# STM32N645 register map
File version: 1.0
CPU: CM55 r0p1, little endian, no MPU, FPU, vendor SysTick, 8 interrupt priority bits
Registers are 32-bit, read-write, reset 0x0 unless marked. A register's access mark holds for its fields unless they carry their own. Offsets are from the block's base; [hi:lo] are bit positions.

## ADC12 — ADC common registers
Base 0x40022300
Same registers: ADC12_S 0x50022300
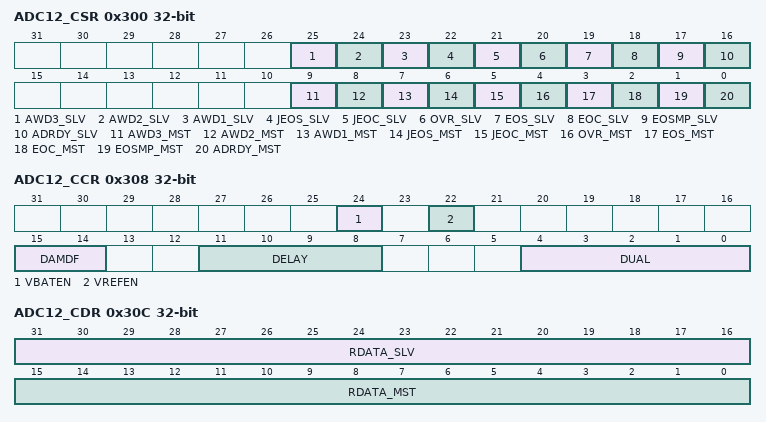
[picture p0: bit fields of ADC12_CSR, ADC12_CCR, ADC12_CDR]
0x300 ADC12_CSR ro — ADC12 common status register
  [25] AWD3_SLV — Analog watchdog 3 flag of the slave ADC
  [24] AWD2_SLV — Analog watchdog 2 flag of the slave ADC
  [23] AWD1_SLV — Analog watchdog 1 flag of the slave ADC
  [22] JEOS_SLV — End of injected sequence flag of the slave ADC
  [21] JEOC_SLV — End of injected conversion flag of the slave ADC
  [20] OVR_SLV — Overrun flag of the slave ADC
  [19] EOS_SLV — End of regular sequence flag of the slave ADC. This bit is a copy of the EOS bit in the corresponding ADC_ISR register.
  [18] EOC_SLV — End of regular conversion of the slave ADC
  [17] EOSMP_SLV — End of Sampling phase flag of the slave ADC
  [16] ADRDY_SLV — Slave ADC ready
  [9] AWD3_MST — Analog watchdog 3 flag of the master ADC
  [8] AWD2_MST — Analog watchdog 2 flag of the master ADC
  [7] AWD1_MST — Analog watchdog 1 flag of the master ADC
  [6] JEOS_MST — End of injected sequence flag of the master ADC
  [5] JEOC_MST — End of injected conversion flag of the master ADC
  [4] OVR_MST — Overrun flag of the master ADC
  [3] EOS_MST — End of regular sequence flag of the master ADC
  [2] EOC_MST — End of regular conversion of the master ADC
  [1] EOSMP_MST — End of Sampling phase flag of the master ADC
  [0] ADRDY_MST — Master ADC ready
0x308 ADC12_CCR — ADC12 common control register
  [24] VBATEN — VBAT enable
    0=V less than sub>BAT less than /sub> channel disabled; 1=V less than sub>BAT less than /sub> channel enabled
  [22] VREFEN — V less than sub>REFINT less than /sub> enable
    0=V less than sub>REFINT less than /sub> channel disabled; 1=V less than sub>REFINT less than /sub> channel enabled
  [15:14] DAMDF — Dual ADC mode data format
    0=Dual ADC mode without data packing (ADCx_CDR and ADCx_CDR2 registers not used); 2=Data formatting mode for any data width (ADCx_CDR data register is used when the data width is less than 16 bits, otherwise ADCx_CDR2 register is used); 3=Data formatting mode for data width lower that 8 bits (ADCx_CDR data register is used)
  [11:8] DELAY — Delay between two sampling phases
  [4:0] DUAL — Dual ADC mode selection
    0=Independent mode; 1=Combined regular simultaneous + Injected simultaneous mode; 2=Combined regular simultaneous + Alternate trigger mode; 3=Combined Interleaved mode + Injected simultaneous mode; 5=Injected simultaneous mode only; 6=Regular simultaneous mode only; 7=Interleaved mode only; 9=Alternate trigger mode only
0x30C ADC12_CDR ro — ADC12 common regular data register for Dual mode
  [31:16] RDATA_SLV — Regular data of the slave ADC
  [15:0] RDATA_MST — Regular data of the master ADC.
0x310 ADC12_CDR2 ro — ADC12 common regular data register for Dual mode
  [31:0] RDATA_ALT — Regular data of the master/slave alternated ADCs.

## CRC — Cyclic redundancy check calculation unit
Base 0x46024C00
Same registers: CRC_S 0x56024C00
0x00 CRC_DR reset 0xFFFFFFFF — CRC data register
  [31:0] DR — Data register bits
0x04 CRC_IDR — CRC independent data register
  [31:0] IDR — General-purpose 32-bit data register bits
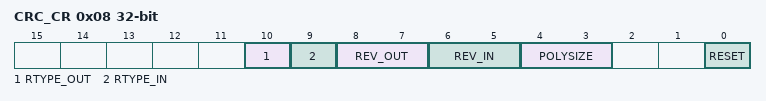
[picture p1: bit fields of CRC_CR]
0x08 CRC_CR — CRC control register
  [10] RTYPE_OUT — Reverse type output
    0=Bit level output; 1=Byte or half-word level output
  [9] RTYPE_IN — Reverse type input
    0=Bit level input; 1=Byte or half-word level input
  [8:7] REV_OUT — Reverse output data
    0=Bit order not affected (RTYPE_OUT = 0 or 1); 1=Bit-reversed output format (RTYPE_OUT = 0) or half-word reversal done by word (RTYPE_OUT = 1); 2=Bit order not affected (RTYPE_OUT = 0) or byte reversal done by word (RTYPE_OUT = 1); 3=Bit order not affected (RTYPE_OUT = 0 or 1)
  [6:5] REV_IN — Reverse input data
    0=Bit order not affected (RTYPE_IN = 0 or 1); 1=Bit reversal done by byte (RTYPE_IN = 0) or half-word reversal done by word (RTYPE_IN = 1); 2=Bit reversal done by half-word (RTYPE_IN = 0) or byte reversal done by word (RTYPE_IN = 1); 3=Bit reversal done by word (RTYPE_IN = 0) or bit order is not affected (RTYPE_IN = 1)
  [4:3] POLYSIZE — Polynomial size
    0=32 bit polynomial; 1=16 bit polynomial; 2=8 bit polynomial; 3=7 bit polynomial
  [0] RESET — RESET bit
0x10 CRC_INIT reset 0xFFFFFFFF — CRC initial value
  [31:0] CRC_INIT — Programmable initial CRC value
0x14 CRC_POL reset 0x4C11DB7 — CRC polynomial
  [31:0] POL — Programmable polynomial
